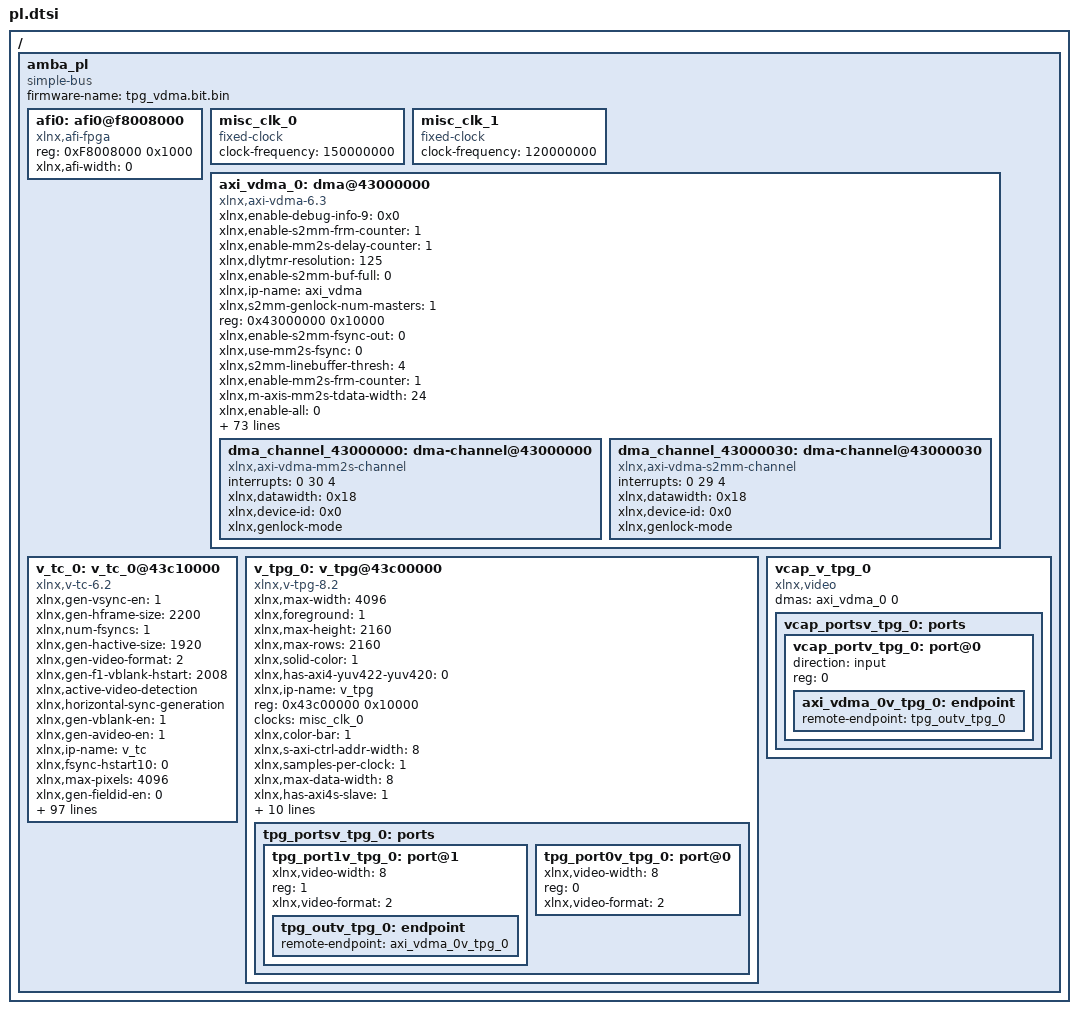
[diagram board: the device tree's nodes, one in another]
/ {
	amba_pl: amba_pl {
		ranges;
		compatible = "simple-bus";
		#address-cells = <1>;
		#size-cells = <1>;
		firmware-name = "tpg_vdma.bit.bin";
		afi0: afi0@f8008000 {
			status = "okay";
			compatible = "xlnx,afi-fpga";
			#address-cells = <1>;
			reg = <0xF8008000 0x1000>;
			#size-cells = <0>;
			xlnx,afi-width = <0>;
		};
		misc_clk_0: misc_clk_0 {
			compatible = "fixed-clock";
			clock-frequency = <150000000>;
			#clock-cells = <0>;
		};
		misc_clk_1: misc_clk_1 {
			compatible = "fixed-clock";
			clock-frequency = <120000000>;
			#clock-cells = <0>;
		};
		axi_vdma_0: dma@43000000 {
			xlnx,enable-debug-info-9 = <0x0>;
			xlnx,enable-s2mm-frm-counter = <1>;
			xlnx,enable-mm2s-delay-counter = <1>;
			xlnx,dlytmr-resolution = <125>;
			xlnx,enable-s2mm-buf-full = <0>;
			xlnx,ip-name = "axi_vdma";
			xlnx,s2mm-genlock-num-masters = <1>;
			reg = <0x43000000 0x10000>;
			xlnx,enable-s2mm-fsync-out = <0>;
			xlnx,use-mm2s-fsync = <0>;
			xlnx,s2mm-linebuffer-thresh = <4>;
			xlnx,enable-mm2s-frm-counter = <1>;
			xlnx,m-axis-mm2s-tdata-width = <24>;
			xlnx,enable-all = <0>;
			xlnx,dynamic-resolution = <1>;
			xlnx,enable-s2mm-rst-out = <0>;
			interrupt-names = "mm2s_introut" , "s2mm_introut";
			xlnx,s2mm-sof-enable = <0x1>;
			xlnx,mm2s-genlock-num-masters = <1>;
			xlnx,enable-mm2s-fsync-out = <0>;
			xlnx,mm2s-linebuffer-thresh = <4>;
			compatible = "xlnx,axi-vdma-6.3" , "xlnx,axi-vdma-1.00.a";
			xlnx,enable-tstvec = <0>;
			interrupt-parent = <&intc>;
			xlnx,s2mm-max-burst-length = <8>;
			xlnx,enable-mm2s-rst-out = <0>;
			xlnx,mm2s-sof-enable = <1>;
			xlnx,include-s2mm-dre = <0x0>;
			xlnx,enable-s2mm-frmstr-reg = <0>;
			xlnx,m-axi-s2mm-data-width = <64>;
			xlnx,enable-s2mm-sts-reg = <0>;
			xlnx,mm2s-max-burst-length = <8>;
			status = "okay";
			xlnx,include-mm2s-dre = <0x0>;
			xlnx,name = "axi_vdma_0";
			xlnx,enable-mm2s-frmstr-reg = <0>;
			interrupts = < 0 30 4 0 29 4 >;
			xlnx,m-axi-mm2s-data-width = <64>;
			xlnx,flush-on-fsync = <0x1>;
			xlnx,include-s2mm-sf = <1>;
			xlnx,single-interface = <0>;
			xlnx,s2mm-linebuffer-depth = <0x200>;
			xlnx,include-s2mm = <0x1>;
			xlnx,addr-width = <32>;
			clocks = <&misc_clk_0>, <&misc_clk_0>, <&misc_clk_1>, <&misc_clk_0>, <&misc_clk_0>;
			xlnx,s-axis-s2mm-tdata-width = <24>;
			xlnx,enable-debug-info-10 = <0>;
			xlnx,addrwidth = <0x20>;
			xlnx,enable-debug-info-11 = <0>;
			xlnx,edk-iptype = "PERIPHERAL";
			xlnx,enable-debug-info-12 = <0>;
			xlnx,use-fsync = <1>;
			xlnx,s2mm-genlock-repeat-en = <1>;
			xlnx,enable-debug-info-13 = <0x0>;
			xlnx,enable-vert-flip = <0x0>;
			xlnx,include-mm2s-sf = <0>;
			xlnx,enable-debug-info-14 = <0x1>;
			xlnx,include-internal-genlock = <0x1>;
			clock-names = "m_axi_mm2s_aclk" , "m_axi_s2mm_aclk" , "m_axis_mm2s_aclk" , "s_axi_lite_aclk" , "s_axis_s2mm_aclk";
			xlnx,enable-debug-info-15 = <0x1>;
			xlnx,mm2s-linebuffer-depth = <0x1000>;
			xlnx,include-mm2s = <0x1>;
			xlnx,s2mm-genlock-mode = <0x2>;
			xlnx,flush-fsync = <0x1>;
			xlnx,select-xpm = <0>;
			xlnx,s2mm-data-width = <0x40>;
			xlnx,num-fstores = <0x3>;
			xlnx,enable-s2mm-param-updt = <0>;
			xlnx,enable-vidparam-reads = <0x1>;
			xlnx,mm2s-genlock-repeat-en = <0>;
			xlnx,prmry-is-aclk-async = <1>;
			xlnx,s2mm-tdata-width = <0x18>;
			#dma-cells = <1>;
			xlnx,enable-vidprmtr-reads = <1>;
			xlnx,mm2s-genlock-mode = <0x3>;
			xlnx,enable-debug-info-0 = <0>;
			xlnx,enable-debug-all = <0x0>;
			xlnx,enable-debug-info-1 = <0x0>;
			xlnx,mm2s-data-width = <0x40>;
			xlnx,enable-debug-info-2 = <0>;
			xlnx,enable-mm2s-param-updt = <0>;
			xlnx,enable-debug-info-3 = <0>;
			xlnx,enable-s2mm-delay-counter = <1>;
			xlnx,enable-debug-info-4 = <0>;
			xlnx,enable-debug-info-5 = <0x0>;
			xlnx,mm2s-tdata-width = <0x18>;
			xlnx,enable-debug-info-6 = <0x1>;
			xlnx,enable-debug-info-7 = <0x1>;
			xlnx,use-s2mm-fsync = <2>;
			xlnx,enable-debug-info-8 = <0>;
			xlnx,enable-mm2s-buf-empty = <0>;
			dma_channel_43000000: dma-channel@43000000 {
				interrupts = < 0 30 4 >;
				xlnx,datawidth = <0x18>;
				xlnx,device-id = <0x0>;
				compatible = "xlnx,axi-vdma-mm2s-channel";
				xlnx,genlock-mode;
			};
			dma_channel_43000030: dma-channel@43000030 {
				interrupts = < 0 29 4 >;
				xlnx,datawidth = <0x18>;
				xlnx,device-id = <0x0>;
				compatible = "xlnx,axi-vdma-s2mm-channel";
				xlnx,genlock-mode;
			};
		};
		v_tc_0: v_tc_0@43c10000 {
			xlnx,gen-vsync-en = <1>;
			xlnx,gen-hframe-size = <2200>;
			xlnx,num-fsyncs = <1>;
			xlnx,gen-hactive-size = <1920>;
			xlnx,gen-video-format = <2>;
			xlnx,gen-f1-vblank-hstart = <2008>;
			xlnx,active-video-detection;
			xlnx,horizontal-sync-generation;
			xlnx,gen-vblank-en = <1>;
			xlnx,gen-avideo-en = <1>;
			xlnx,ip-name = "v_tc";
			xlnx,fsync-hstart10 = <0>;
			xlnx,max-pixels = <4096>;
			xlnx,gen-fieldid-en = <0>;
			reg = <0x43c10000 0x10000>;
			xlnx,det-vblank-en = <1>;
			xlnx,fsync-hstart11 = <0>;
			xlnx,fsync-hstart12 = <0>;
			xlnx,pixels-per-clock = <0x4>;
			xlnx,gen-interlaced = <0>;
			xlnx,det-avideo-en = <1>;
			xlnx,fsync-hstart13 = <0>;
			xlnx,fsync-hstart14 = <0>;
			xlnx,gen-f0-vblank-hend = <2008>;
			xlnx,fsync-hstart15 = <0>;
			xlnx,det-hsync-en = <1>;
			xlnx,enable-generation;
			xlnx,gen-avideo-polarity = <1>;
			xlnx,max-lines-per-frame = <4096>;
			xlnx,has-axi4-lite = <1>;
			compatible = "xlnx,v-tc-6.2" , "xlnx,bridge-v-tc-6.1";
			xlnx,max-clocks-per-line = <4096>;
			xlnx,gen-f0-vframe-size = <1125>;
			xlnx,gen-f0-vblank-hstart = <2008>;
			xlnx,max-lines = <4096>;
			xlnx,gen-f0-vsync-vstart = <1083>;
			xlnx,horizontal-blank-generation;
			xlnx,gen-hsync-end = <2052>;
			xlnx,gen-f0-vsync-hstart = <2008>;
			xlnx,gen-f1-vsync-hend = <2008>;
			xlnx,vertical-blank-detection;
			xlnx,gen-vsync-polarity = <1>;
			xlnx,fsync-vstart0 = <0>;
			xlnx,gen-hsync-polarity = <1>;
			xlnx,fsync-vstart1 = <0>;
			status = "okay";
			xlnx,fsync-vstart2 = <0>;
			xlnx,gen-hsync-start = <2008>;
			xlnx,gen-f0-vsync-vend = <1088>;
			xlnx,fsync-vstart3 = <0>;
			xlnx,vertical-sync-detection;
			xlnx,frame-syncs = <1>;
			xlnx,fsync-vstart4 = <0>;
			xlnx,gen-vactive-size = <1080>;
			xlnx,name = "v_tc_0";
			xlnx,fsync-vstart5 = <0>;
			xlnx,detector;
			xlnx,gen-achroma-en = <0>;
			xlnx,fsync-vstart6 = <0>;
			xlnx,det-fieldid-en = <0>;
			xlnx,fsync-vstart7 = <0>;
			xlnx,gen-hsync-en = <1>;
			xlnx,fsync-vstart8 = <0>;
			xlnx,fsync-vstart10 = <0>;
			xlnx,fsync-vstart9 = <0>;
			xlnx,fsync-vstart11 = <0>;
			xlnx,arbitrary-res-en = /bits/ 8 <0x0>;
			xlnx,fsync-vstart12 = <0>;
			xlnx,fsync-vstart13 = <0>;
			clocks = <&misc_clk_1>, <&misc_clk_0>;
			xlnx,fsync-vstart14 = <0>;
			xlnx,fsync-vstart15 = <0>;
			xlnx,enable-detection;
			xlnx,gen-cparity = <0>;
			xlnx,edk-iptype = "PERIPHERAL";
			xlnx,vertical-sync-generation;
			xlnx,gen-f1-vblank-hend = <2008>;
			xlnx,det-vsync-en = <1>;
			xlnx,gen-vblank-polarity = <1>;
			xlnx,fsync-hstart0 = <0>;
			clock-names = "clk" , "s_axi_aclk";
			xlnx,interlace-en = <0>;
			xlnx,gen-auto-switch = <0>;
			xlnx,fsync-hstart1 = <0>;
			xlnx,fsync-hstart2 = <0>;
			xlnx,active-video-generation;
			xlnx,fsync-hstart3 = <0>;
			xlnx,fsync-hstart4 = <0>;
			xlnx,horizontal-blank-detection;
			xlnx,fsync-hstart5 = <0>;
			xlnx,gen-f1-vframe-size = <1125>;
			xlnx,fsync-hstart6 = <0>;
			xlnx,fsync-hstart7 = <0>;
			xlnx,fsync-hstart8 = <0>;
			xlnx,gen-hblank-en = <1>;
			xlnx,fsync-hstart9 = <0>;
			xlnx,horizontal-sync-detection;
			xlnx,gen-f1-vsync-vend = <1088>;
			xlnx,detect-en = <1>;
			xlnx,det-hblank-en = <1>;
			xlnx,vid-ppc = <4>;
			xlnx,has-intc-if = <0>;
			xlnx,generate-en = <1>;
			xlnx,gen-achroma-polarity = <1>;
			xlnx,sync-en = <0>;
			xlnx,det-achroma-en = <0>;
			xlnx,generator;
			xlnx,gen-f1-vsync-vstart = <1083>;
			xlnx,vertical-blank-generation;
			xlnx,gen-hblank-polarity = <1>;
			xlnx,video-mode = "1080p";
			xlnx,gen-fieldid-polarity = <1>;
			xlnx,gen-f1-vsync-hstart = <2008>;
			xlnx,gen-f0-vsync-hend = <2008>;
		};
		v_tpg_0: v_tpg@43c00000 {
			compatible = "xlnx,v-tpg-8.2" , "xlnx,v-tpg-8.0";
			xlnx,max-width = <4096>;
			xlnx,foreground = <1>;
			xlnx,max-height = <2160>;
			xlnx,max-rows = <2160>;
			xlnx,solid-color = <1>;
			xlnx,has-axi4-yuv422-yuv420 = <0>;
			xlnx,ip-name = "v_tpg";
			reg = <0x43c00000 0x10000>;
			clocks = <&misc_clk_0>;
			xlnx,color-bar = <1>;
			xlnx,s-axi-ctrl-addr-width = <8>;
			xlnx,samples-per-clock = <1>;
			xlnx,max-data-width = <8>;
			xlnx,has-axi4s-slave = <1>;
			xlnx,ppc = <1>;
			xlnx,max-cols = <4096>;
			xlnx,edk-iptype = "PERIPHERAL";
			status = "okay";
			clock-names = "ap_clk";
			xlnx,zone-plate = <1>;
			xlnx,num-video-components = <3>;
			xlnx,ramp = <1>;
			xlnx,color-sweep = <1>;
			xlnx,s-axi-ctrl-data-width = <32>;
			xlnx,display-port = <1>;
			xlnx,name = "v_tpg_0";
			tpg_portsv_tpg_0: ports {
				#address-cells = <1>;
				#size-cells = <0>;
				tpg_port1v_tpg_0: port@1 {
					xlnx,video-width = <8>;
					reg = <1>;
					xlnx,video-format = <2>;
					tpg_outv_tpg_0: endpoint {
						remote-endpoint = <&axi_vdma_0v_tpg_0>;
					};
				};
				tpg_port0v_tpg_0: port@0 {
					xlnx,video-width = <8>;
					reg = <0>;
					xlnx,video-format = <2>;
				};
			};
		};
		vcap_v_tpg_0 {
			compatible = "xlnx,video";
			dmas = <&axi_vdma_0 0>;
			dma-names = "port0";
			vcap_portsv_tpg_0: ports {
				#address-cells = <1>;
				#size-cells = <0>;
				vcap_portv_tpg_0: port@0 {
					direction = "input";
					reg = <0>;
					axi_vdma_0v_tpg_0: endpoint {
						remote-endpoint = <&tpg_outv_tpg_0>;
					};
				};
			};
		};
	};
};
